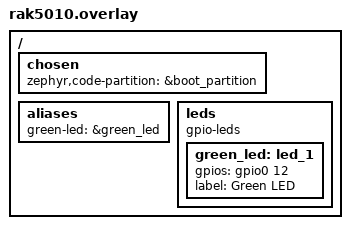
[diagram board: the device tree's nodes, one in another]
/ {
	chosen {
		zephyr,code-partition = &boot_partition;
	};

	aliases {
		green-led = &green_led;
	};

	leds {
		compatible = "gpio-leds";
		green_led: led_1 {
			gpios = <&gpio0 12 GPIO_ACTIVE_HIGH>;
			label = "Green LED";
		};
	};
};
